AUTOSAR XML (schema 4-2-2)
package /ComponentTypes
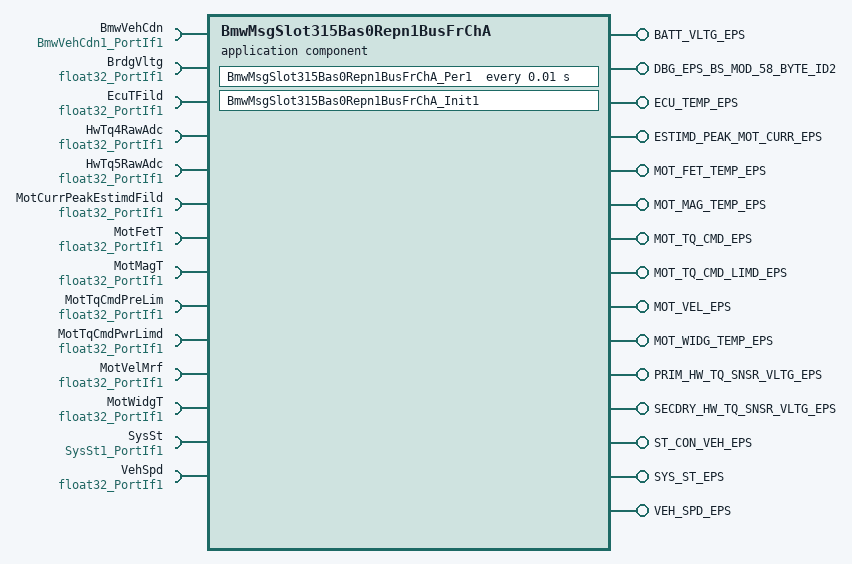
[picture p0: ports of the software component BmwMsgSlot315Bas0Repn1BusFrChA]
  application sw component type BmwMsgSlot315Bas0Repn1BusFrChA
    15 x provide port:
      BATT_VLTG_EPS: nonqueued-sender-com-spec{data-element=BATT_VLTG_EPS, init-value=0}, provided-interface=BATT_VLTG_EPS
      DBG_EPS_BS_MOD_58_BYTE_ID2: nonqueued-sender-com-spec{data-element=DBG_EPS_BS_MOD_58_BYTE_ID2, init-value=1}, provided-interface=DBG_EPS_BS_MOD_58_BYTE_ID2
      ECU_TEMP_EPS: nonqueued-sender-com-spec{data-element=ECU_TEMP_EPS, init-value=75}, provided-interface=ECU_TEMP_EPS
      ESTIMD_PEAK_MOT_CURR_EPS: nonqueued-sender-com-spec{data-element=ESTIMD_PEAK_MOT_CURR_EPS, init-value=0}, provided-interface=ESTIMD_PEAK_MOT_CURR_EPS
      MOT_FET_TEMP_EPS: nonqueued-sender-com-spec{data-element=MOT_FET_TEMP_EPS, init-value=75}, provided-interface=MOT_FET_TEMP_EPS
      MOT_MAG_TEMP_EPS: nonqueued-sender-com-spec{data-element=MOT_MAG_TEMP_EPS, init-value=75}, provided-interface=MOT_MAG_TEMP_EPS
      MOT_TQ_CMD_EPS: nonqueued-sender-com-spec{data-element=MOT_TQ_CMD_EPS, init-value=880}, provided-interface=MOT_TQ_CMD_EPS
      MOT_TQ_CMD_LIMD_EPS: nonqueued-sender-com-spec{data-element=MOT_TQ_CMD_LIMD_EPS, init-value=880}, provided-interface=MOT_TQ_CMD_LIMD_EPS
      MOT_VEL_EPS: nonqueued-sender-com-spec{data-element=MOT_VEL_EPS, init-value=27000}, provided-interface=MOT_VEL_EPS
      MOT_WIDG_TEMP_EPS: nonqueued-sender-com-spec{data-element=MOT_WIDG_TEMP_EPS, init-value=75}, provided-interface=MOT_WIDG_TEMP_EPS
      PRIM_HW_TQ_SNSR_VLTG_EPS: nonqueued-sender-com-spec{data-element=PRIM_HW_TQ_SNSR_VLTG_EPS, init-value=0}, provided-interface=PRIM_HW_TQ_SNSR_VLTG_EPS
      SECDRY_HW_TQ_SNSR_VLTG_EPS: nonqueued-sender-com-spec{data-element=SECDRY_HW_TQ_SNSR_VLTG_EPS, init-value=0}, provided-interface=SECDRY_HW_TQ_SNSR_VLTG_EPS
      ST_CON_VEH_EPS: nonqueued-sender-com-spec{data-element=ST_CON_VEH_EPS, init-value=15}, provided-interface=ST_CON_VEH_EPS
      SYS_ST_EPS: nonqueued-sender-com-spec{data-element=SYS_ST_EPS, init-value=3}, provided-interface=SYS_ST_EPS
      VEH_SPD_EPS: nonqueued-sender-com-spec{data-element=VEH_SPD_EPS, init-value=0}, provided-interface=VEH_SPD_EPS
    14 x require port:
      BmwVehCdn: nonqueued-receiver-com-spec{data-element=Val, filter=data-filter-type=ALWAYS, init-value=15}, required-interface=BmwVehCdn1_PortIf1
      BrdgVltg: nonqueued-receiver-com-spec{data-element=Val, filter=data-filter-type=ALWAYS, init-value=6}, required-interface=float32_PortIf1
      EcuTFild: nonqueued-receiver-com-spec{data-element=Val, filter=data-filter-type=ALWAYS, init-value=25}, required-interface=float32_PortIf1
      HwTq4RawAdc: nonqueued-receiver-com-spec{data-element=Val, filter=data-filter-type=ALWAYS, init-value=0}, required-interface=float32_PortIf1
      HwTq5RawAdc: nonqueued-receiver-com-spec{data-element=Val, filter=data-filter-type=ALWAYS, init-value=0}, required-interface=float32_PortIf1
      MotCurrPeakEstimdFild: nonqueued-receiver-com-spec{data-element=Val, filter=data-filter-type=ALWAYS, init-value=0}, required-interface=float32_PortIf1
      MotFetT: nonqueued-receiver-com-spec{data-element=Val, filter=data-filter-type=ALWAYS, init-value=0}, required-interface=float32_PortIf1
      MotMagT: nonqueued-receiver-com-spec{data-element=Val, filter=data-filter-type=ALWAYS, init-value=0}, required-interface=float32_PortIf1
      MotTqCmdPreLim: nonqueued-receiver-com-spec{data-element=Val, filter=data-filter-type=ALWAYS, init-value=0}, required-interface=float32_PortIf1
      MotTqCmdPwrLimd: nonqueued-receiver-com-spec{data-element=Val, filter=data-filter-type=ALWAYS, init-value=0}, required-interface=float32_PortIf1
      MotVelMrf: nonqueued-receiver-com-spec{data-element=Val, filter=data-filter-type=ALWAYS, init-value=0}, required-interface=float32_PortIf1
      MotWidgT: nonqueued-receiver-com-spec{data-element=Val, filter=data-filter-type=ALWAYS, init-value=0}, required-interface=float32_PortIf1
      SysSt: nonqueued-receiver-com-spec{data-element=Val, filter=data-filter-type=ALWAYS, init-value=3}, required-interface=SysSt1_PortIf1
      VehSpd: nonqueued-receiver-com-spec{data-element=Val, filter=data-filter-type=ALWAYS, init-value=0}, required-interface=float32_PortIf1
    behavior BmwMsgSlot315Bas0Repn1BusFrChA_InternalBehavior
      ar-typed-per-instance-memorys:
        data PerCntrFlg: sw-calibration-access=READ-ONLY, type=boolean
      init event BmwMsgSlot315Bas0Repn1BusFrChA_InitEvent: start-on-event=BmwMsgSlot315Bas0Repn1BusFrChA_Init1
      timing event TMT_BmwMsgSlot315Bas0Repn1BusFrChA_Per1: start-on-event=BmwMsgSlot315Bas0Repn1BusFrChA_Per1, period=0.01
      port-api-options:
        enable-take-address=false, error-handling=NO-TRANSFORMER-ERROR-HANDLING, indirect-api=false, port=BATT_VLTG_EPS
        enable-take-address=false, error-handling=NO-TRANSFORMER-ERROR-HANDLING, indirect-api=false, port=BmwVehCdn
        enable-take-address=false, error-handling=NO-TRANSFORMER-ERROR-HANDLING, indirect-api=false, port=BrdgVltg
        enable-take-address=false, error-handling=NO-TRANSFORMER-ERROR-HANDLING, indirect-api=false, port=DBG_EPS_BS_MOD_58_BYTE_ID2
        enable-take-address=false, error-handling=NO-TRANSFORMER-ERROR-HANDLING, indirect-api=false, port=ECU_TEMP_EPS
        enable-take-address=false, error-handling=NO-TRANSFORMER-ERROR-HANDLING, indirect-api=false, port=EcuTFild
        enable-take-address=false, error-handling=NO-TRANSFORMER-ERROR-HANDLING, indirect-api=false, port=ESTIMD_PEAK_MOT_CURR_EPS
        enable-take-address=false, error-handling=NO-TRANSFORMER-ERROR-HANDLING, indirect-api=false, port=HwTq4RawAdc
        enable-take-address=false, error-handling=NO-TRANSFORMER-ERROR-HANDLING, indirect-api=false, port=HwTq5RawAdc
        enable-take-address=false, error-handling=NO-TRANSFORMER-ERROR-HANDLING, indirect-api=false, port=MOT_FET_TEMP_EPS
        enable-take-address=false, error-handling=NO-TRANSFORMER-ERROR-HANDLING, indirect-api=false, port=MOT_MAG_TEMP_EPS
        enable-take-address=false, error-handling=NO-TRANSFORMER-ERROR-HANDLING, indirect-api=false, port=MOT_TQ_CMD_EPS
        enable-take-address=false, error-handling=NO-TRANSFORMER-ERROR-HANDLING, indirect-api=false, port=MOT_TQ_CMD_LIMD_EPS
        enable-take-address=false, error-handling=NO-TRANSFORMER-ERROR-HANDLING, indirect-api=false, port=MOT_VEL_EPS
        enable-take-address=false, error-handling=NO-TRANSFORMER-ERROR-HANDLING, indirect-api=false, port=MOT_WIDG_TEMP_EPS
        enable-take-address=false, error-handling=NO-TRANSFORMER-ERROR-HANDLING, indirect-api=false, port=MotCurrPeakEstimdFild
        enable-take-address=false, error-handling=NO-TRANSFORMER-ERROR-HANDLING, indirect-api=false, port=MotFetT
        enable-take-address=false, error-handling=NO-TRANSFORMER-ERROR-HANDLING, indirect-api=false, port=MotMagT
        enable-take-address=false, error-handling=NO-TRANSFORMER-ERROR-HANDLING, indirect-api=false, port=MotTqCmdPreLim
        enable-take-address=false, error-handling=NO-TRANSFORMER-ERROR-HANDLING, indirect-api=false, port=MotTqCmdPwrLimd
        enable-take-address=false, error-handling=NO-TRANSFORMER-ERROR-HANDLING, indirect-api=false, port=MotVelMrf
        enable-take-address=false, error-handling=NO-TRANSFORMER-ERROR-HANDLING, indirect-api=false, port=MotWidgT
        enable-take-address=false, error-handling=NO-TRANSFORMER-ERROR-HANDLING, indirect-api=false, port=PRIM_HW_TQ_SNSR_VLTG_EPS
        enable-take-address=false, error-handling=NO-TRANSFORMER-ERROR-HANDLING, indirect-api=false, port=SECDRY_HW_TQ_SNSR_VLTG_EPS
        enable-take-address=false, error-handling=NO-TRANSFORMER-ERROR-HANDLING, indirect-api=false, port=ST_CON_VEH_EPS
        enable-take-address=false, error-handling=NO-TRANSFORMER-ERROR-HANDLING, indirect-api=false, port=SYS_ST_EPS
        enable-take-address=false, error-handling=NO-TRANSFORMER-ERROR-HANDLING, indirect-api=false, port=SysSt
        enable-take-address=false, error-handling=NO-TRANSFORMER-ERROR-HANDLING, indirect-api=false, port=VEH_SPD_EPS
        enable-take-address=false, error-handling=NO-TRANSFORMER-ERROR-HANDLING, indirect-api=false, port=VehSpd
      runnable BmwMsgSlot315Bas0Repn1BusFrChA_Init1
      runnable BmwMsgSlot315Bas0Repn1BusFrChA_Per1
        data-receive-point-by-arguments:
          14 x access:
            REC_BmwVehCdn_Val: accessed-variable=BmwVehCdn.Val
            REC_BrdgVltg_Val: accessed-variable=BrdgVltg.Val
            REC_EcuTFild_Val: accessed-variable=EcuTFild.Val
            REC_HwTq4RawAdc_Val: accessed-variable=HwTq4RawAdc.Val
            REC_HwTq5RawAdc_Val: accessed-variable=HwTq5RawAdc.Val
            REC_MotCurrPeakEstimdFild_Val: accessed-variable=MotCurrPeakEstimdFild.Val
            REC_MotFetT_Val: accessed-variable=MotFetT.Val
            REC_MotMagT_Val: accessed-variable=MotMagT.Val
            REC_MotTqCmdPreLim_Val: accessed-variable=MotTqCmdPreLim.Val
            REC_MotTqCmdPwrLimd_Val: accessed-variable=MotTqCmdPwrLimd.Val
            REC_MotVelMrf_Val: accessed-variable=MotVelMrf.Val
            REC_MotWidgT_Val: accessed-variable=MotWidgT.Val
            REC_SysSt_Val: accessed-variable=SysSt.Val
            REC_VehSpd_Val: accessed-variable=VehSpd.Val
        data-send-points:
          15 x access:
            SEND_BATT_VLTG_EPS_BATT_VLTG_EPS: accessed-variable=BATT_VLTG_EPS.BATT_VLTG_EPS
            SEND_DBG_EPS_BS_MOD_58_BYTE_ID2_DBG_EPS_BS_MOD_58_BYTE_ID2: accessed-variable=DBG_EPS_BS_MOD_58_BYTE_ID2.DBG_EPS_BS_MOD_58_BYTE_ID2
            SEND_ECU_TEMP_EPS_ECU_TEMP_EPS: accessed-variable=ECU_TEMP_EPS.ECU_TEMP_EPS
            SEND_ESTIMD_PEAK_MOT_CURR_EPS_ESTIMD_PEAK_MOT_CURR_EPS: accessed-variable=ESTIMD_PEAK_MOT_CURR_EPS.ESTIMD_PEAK_MOT_CURR_EPS
            SEND_MOT_FET_TEMP_EPS_MOT_FET_TEMP_EPS: accessed-variable=MOT_FET_TEMP_EPS.MOT_FET_TEMP_EPS
            SEND_MOT_MAG_TEMP_EPS_MOT_MAG_TEMP_EPS: accessed-variable=MOT_MAG_TEMP_EPS.MOT_MAG_TEMP_EPS
            SEND_MOT_TQ_CMD_EPS_MOT_TQ_CMD_EPS: accessed-variable=MOT_TQ_CMD_EPS.MOT_TQ_CMD_EPS
            SEND_MOT_TQ_CMD_LIMD_EPS_MOT_TQ_CMD_LIMD_EPS: accessed-variable=MOT_TQ_CMD_LIMD_EPS.MOT_TQ_CMD_LIMD_EPS
            SEND_MOT_VEL_EPS_MOT_VEL_EPS: accessed-variable=MOT_VEL_EPS.MOT_VEL_EPS
            SEND_MOT_WIDG_TEMP_EPS_MOT_WIDG_TEMP_EPS: accessed-variable=MOT_WIDG_TEMP_EPS.MOT_WIDG_TEMP_EPS
            SEND_PRIM_HW_TQ_SNSR_VLTG_EPS_PRIM_HW_TQ_SNSR_VLTG_EPS: accessed-variable=PRIM_HW_TQ_SNSR_VLTG_EPS.PRIM_HW_TQ_SNSR_VLTG_EPS
            SEND_SECDRY_HW_TQ_SNSR_VLTG_EPS_SECDRY_HW_TQ_SNSR_VLTG_EPS: accessed-variable=SECDRY_HW_TQ_SNSR_VLTG_EPS.SECDRY_HW_TQ_SNSR_VLTG_EPS
            SEND_ST_CON_VEH_EPS_ST_CON_VEH_EPS: accessed-variable=ST_CON_VEH_EPS.ST_CON_VEH_EPS
            SEND_SYS_ST_EPS_SYS_ST_EPS: accessed-variable=SYS_ST_EPS.SYS_ST_EPS
            SEND_VEH_SPD_EPS_VEH_SPD_EPS: accessed-variable=VEH_SPD_EPS.VEH_SPD_EPS
  swc implementation BmwMsgSlot315Bas0Repn1BusFrChA_Implementation: behavior=BmwMsgSlot315Bas0Repn1BusFrChA_InternalBehavior
    code-descriptors:
      code Default: artifact-descriptors=autosar-engineering-object={short-label=Default, category=SWSRC}
